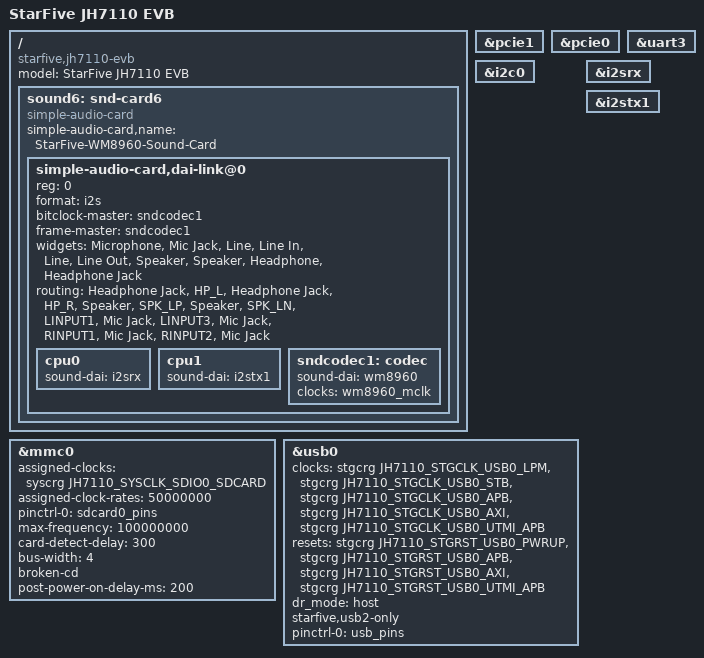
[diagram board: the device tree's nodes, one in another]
// SPDX-License-Identifier: GPL-2.0 OR MIT
/*
 * Copyright (C) 2022 StarFive Technology Co., Ltd.
 */

/dts-v1/;
#include "jh7110-evb.dtsi"

/ {
	model = "StarFive JH7110 EVB";
	compatible = "starfive,jh7110-evb", "starfive,jh7110";

	/* i2s + wm8960 */
	sound6: snd-card6 {
		compatible = "simple-audio-card";
		#address-cells = <1>;
		#size-cells = <0>;

		simple-audio-card,name = "StarFive-WM8960-Sound-Card";
		simple-audio-card,dai-link@0 {
			reg = <0>;
			status = "okay";
			format = "i2s";
			bitclock-master = <&sndcodec1>;
			frame-master = <&sndcodec1>;

			widgets = "Microphone", "Mic Jack",
				  "Line", "Line In",
				  "Line", "Line Out",
				  "Speaker", "Speaker",
				  "Headphone", "Headphone Jack";
			routing = "Headphone Jack", "HP_L",
				  "Headphone Jack", "HP_R",
				  "Speaker", "SPK_LP",
				  "Speaker", "SPK_LN",
				  "LINPUT1", "Mic Jack",
				  "LINPUT3", "Mic Jack",
				  "RINPUT1", "Mic Jack",
				  "RINPUT2", "Mic Jack";
			cpu0 {
				sound-dai = <&i2srx>;
			};
			cpu1 {
				sound-dai = <&i2stx1>;
			};

			sndcodec1:codec {
				sound-dai = <&wm8960>;
				clocks = <&wm8960_mclk>;
				clock-names = "mclk";
			};
		};
	};
};

&mmc0 {
	assigned-clocks = <&syscrg JH7110_SYSCLK_SDIO0_SDCARD>;
	assigned-clock-rates = <50000000>;
	pinctrl-names = "default";
	pinctrl-0 = <&sdcard0_pins>;
	max-frequency = <100000000>;
	card-detect-delay = <300>;
	bus-width = <4>;
	broken-cd;
	post-power-on-delay-ms = <200>;
	status = "okay";
};

&pcie1 {
	status = "okay";
};

&pcie0 {
	status = "okay";
};

&uart3 {
	status = "okay";
};

&i2c0 {
	status = "okay";
};

&usb0 {
	clocks = <&stgcrg JH7110_STGCLK_USB0_LPM>,
		 <&stgcrg JH7110_STGCLK_USB0_STB>,
		 <&stgcrg JH7110_STGCLK_USB0_APB>,
		 <&stgcrg JH7110_STGCLK_USB0_AXI>,
		 <&stgcrg JH7110_STGCLK_USB0_UTMI_APB>;
	clock-names = "lpm", "stb", "apb", "axi", "utmi_apb";
	resets = <&stgcrg JH7110_STGRST_USB0_PWRUP>,
		 <&stgcrg JH7110_STGRST_USB0_APB>,
		 <&stgcrg JH7110_STGRST_USB0_AXI>,
		 <&stgcrg JH7110_STGRST_USB0_UTMI_APB>;
	reset-names = "pwrup", "apb", "axi", "utmi_apb";
	dr_mode = "host"; /*host or peripheral*/
	starfive,usb2-only;
	pinctrl-names = "default";
	pinctrl-0 = <&usb_pins>;
	status = "okay";
};

&i2srx {
	status = "okay";
};

&i2stx1 {
	status = "okay";
};

